# LPC408x_7x register map
File version: 0.7
CPU: CM4 r0p0, little endian, no MPU, no FPU, 3 interrupt priority bits
Registers are 32-bit, read-write, reset 0x0 unless marked. A register's access mark holds for its fields unless they carry their own. Offsets are from the block's base; [hi:lo] are bit positions; {n}, {i} and the like mark numbered series; 'fields as' and 'values as' point back to an identical list.

## UART4
Base 0x400A4000
0x00 RBR ro reset not defined read-modifies — Receiver Buffer Register. Contains the next received character to be read (DLAB =0).
  [7:0] RBR — The UART4 Receiver Buffer Register contains the oldest received byte in the UART4 Rx FIFO.
0x00 THR wo reset not defined (alternate view of RBR) — Transmit Holding Register. The next character to be transmitted is written here (DLAB =0).
  [7:0] THR — Writing to the UART4 Transmit Holding Register causes the data to be stored in the UART4 transmit FIFO. The byte will be sent when it reaches the bottom of the FIFO and the transmitter is available.
0x00 DLL reset 0x1 (alternate view of RBR) — Divisor Latch LSB. Least significant byte of the baud rate divisor value. The full divisor is used to generate a baud rate from the fractional rate divider (DLAB =1).
  [7:0] DLLSB — The UART4 Divisor Latch LSB Register, along with the U4DLM register, determines the baud rate of the UART4.
0x04 DLM reset 0x1 — Divisor Latch MSB. Most significant byte of the baud rate divisor value. The full divisor is used to generate a baud rate from the fractional rate divider (DLAB =1).
  [7:0] DLMSB — The UART4 Divisor Latch MSB Register, along with the U0DLL register, determines the baud rate of the UART4.
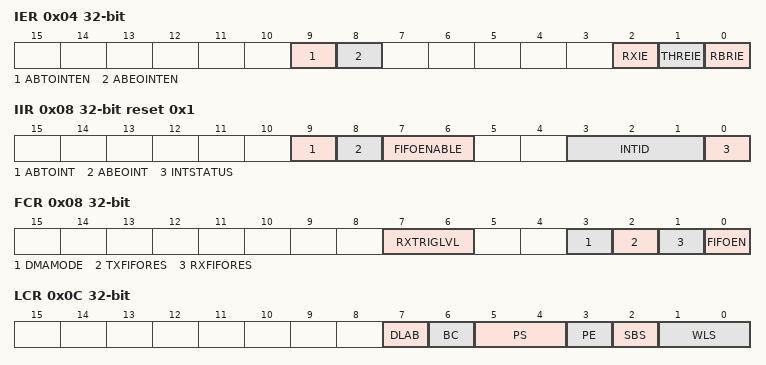
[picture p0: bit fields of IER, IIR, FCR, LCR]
0x04 IER (alternate view of DLM) — Interrupt Enable Register. Contains individual interrupt enable bits for the 7 potential UART interrupts (DLAB =0).
  [9] ABTOINTEN — Enables the auto-baud time-out interrupt.
    0=DISABLE_AUTO_BAUD_TI (Disable auto-baud time-out Interrupt.); 1=ENABLE_AUTO_BAUD_TIM (Enable auto-baud time-out Interrupt.)
  [8] ABEOINTEN — Enables the end of auto-baud interrupt.
    0=DISABLE_END_OF_AUTO_ (Disable end of auto-baud Interrupt.); 1=ENABLE_END_OF_AUTO_B (Enable end of auto-baud Interrupt.)
  [2] RXIE — RX Line Status Interrupt Enable. Enables the UARTn RX line status interrupts. The status of this interrupt can be read from UnLSR[4:1].
    0=DISABLE_THE_RX_LINE_ (Disable the RX line status interrupts.); 1=ENABLE_THE_RX_LINE_S (Enable the RX line status interrupts.)
  [1] THREIE — THRE Interrupt Enable. Enables the THRE interrupt for UARTn. The status of this can be read from UnLSR[5].
    0=DISABLE_THE_THRE_INT (Disable the THRE interrupts.); 1=ENABLE_THE_THRE_INTE (Enable the THRE interrupts.)
  [0] RBRIE — RBR Interrupt Enable. Enables the Receive Data Available interrupt for UARTn. It also controls the Character Receive Time-out interrupt.
    0=DISABLE_THE_RDA_INTE (Disable the RDA interrupts.); 1=ENABLE_THE_RDA_INTER (Enable the RDA interrupts.)
0x08 IIR ro reset 0x1 — Interrupt ID Register. Identifies which interrupt(s) are pending.
  [9] ABTOINT — Auto-baud time-out interrupt. True if auto-baud has timed out and interrupt is enabled.
  [8] ABEOINT — End of auto-baud interrupt. True if auto-baud has finished successfully and interrupt is enabled.
  [7:6] FIFOENABLE — Copies of U4FCR[0].
  [3:1] INTID — Interrupt identification. U4IER[3:1] identifies an interrupt corresponding to the UART4 Rx or TX FIFO. All other combinations of U4IER[3:1] not listed below are reserved (000,100,101,111).
    3=1_RECEIVE_LINE_S (1 - Receive Line Status (RLS).); 2=2A__RECEIVE_DATA_AV (2a - Receive Data Available (RDA).); 6=2B__CHARACTER_TIME_ (2b - Character Time-out Indicator (CTI).); 1=3_THRE_INTERRUPT
  [0] INTSTATUS — Interrupt status. Note that U4IIR[0] is active low. The pending interrupt can be determined by evaluating U4IIR[3:1].
    0=AT_LEAST_ONE_INTERRU (At least one interrupt is pending.); 1=NO_INTERRUPT_IS_PEND (No interrupt is pending.)
0x08 FCR wo (alternate view of IIR) — FIFO Control Register. Controls UART FIFO usage and modes.
  [7:6] RXTRIGLVL — RX Trigger Level. These two bits determine how many receiver UARTn FIFO characters must be written before an interrupt or DMA request is activated.
    0=TRIGGER_LEVEL_0_1_C (Trigger level 0 (1 character or 0x01).); 1=TRIGGER_LEVEL_1_4_C (Trigger level 1 (4 characters or 0x04).); 2=TRIGGER_LEVEL_2_8_C (Trigger level 2 (8 characters or 0x08).); 3=TRIGGER_LEVEL_3_14_ (Trigger level 3 (14 characters or 0x0E).)
  [3] DMAMODE — DMA Mode Select. When the FIFO enable (bit 0 of this register) is set, this bit selects the DMA mode. See Section 20.6.6.1.
  [2] TXFIFORES — TX FIFO Reset.
    0=NO_IMPACT_ON_EITHER_ (No impact on either of UARTn FIFOs.); 1=WRITING_A_LOGIC_1_TO (Writing a logic 1 to UnFCR[2] will clear all bytes in UARTn TX FIFO, reset the pointer logic. This bit is self-clearing.)
  [1] RXFIFORES — RX FIFO Reset.
    0=NO_IMPACT_ON_EITHER_ (No impact on either of UARTn FIFOs.); 1=WRITING_A_LOGIC_1_TO (Writing a logic 1 to UnFCR[1] will clear all bytes in UARTn Rx FIFO, reset the pointer logic. This bit is self-clearing.)
  [0] FIFOEN — FIFO Enable.
    0=UARTN_FIFOS_ARE_DISA (UARTn FIFOs are disabled. Must not be used in the application.); 1=ACTIVE_HIGH_ENABLE_F (Active high enable for both UARTn Rx and TX FIFOs and UnFCR[7:1] access. This bit must be set for proper UART operation. Any transition on this bit will automatically clear the related UART FIFOs.)
0x0C LCR — Line Control Register. Contains controls for frame formatting and break generation.
  [7] DLAB — Divisor Latch Access Bit
    0=DISABLE_ACCESS_TO_DI (Disable access to Divisor Latches.); 1=ENABLE_ACCESS_TO_DIV (Enable access to Divisor Latches.)
  [6] BC — Break Control
    0=DISABLE_BREAK_TRANSM (Disable break transmission.); 1=ENABLE_BREAK_TRANSMI (Enable break transmission. Output pin UARTn TXD is forced to logic 0 when UnLCR[6] is active high.)
  [5:4] PS — Parity Select
    0=ODD_PARITY_NUMBER_O (Odd parity. Number of 1s in the transmitted character and the attached parity bit will be odd.); 1=EVEN_PARITY_NUMBER_ (Even Parity. Number of 1s in the transmitted character and the attached parity bit will be even.); 2=FORCED_1_STICK_PARIT (Forced 1 stick parity.); 3=FORCED_0_STICK_PARIT (Forced 0 stick parity.)
  [3] PE — Parity Enable.
    0=DISABLE_PARITY_GENER (Disable parity generation and checking.); 1=ENABLE_PARITY_GENERA (Enable parity generation and checking.)
  [2] SBS — Stop Bit Select
    0=1_STOP_BIT_; 1=2_STOP_BITS_1_5_IF_ (2 stop bits (1.5 if UnLCR[1:0]=00).)
  [1:0] WLS — Word Length Select.
    {v}={v+5}_BIT_CHARACTER_LENG ({v+5}-bit character length) (v=0..3)
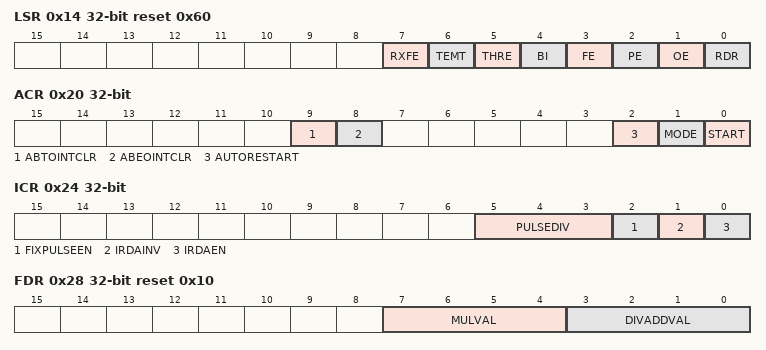
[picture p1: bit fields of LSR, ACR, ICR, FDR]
0x14 LSR ro reset 0x60 read-modifies — Line Status Register. Contains flags for transmit and receive status, including line errors.
  [7] RXFE — Error in RX FIFO . UnLSR[7] is set when a character with a Rx error such as framing error, parity error or break interrupt, is loaded into the UnRBR. This bit is cleared when the UnLSR register is read and there are no subsequent errors in the UARTn FIFO.
    0=UNRBR_CONTAINS_NO_UA (UnRBR contains no UARTn RX errors or UnFCR[0]=0.); 1=UARTN_RBR_CONTAINS_A (UARTn RBR contains at least one UARTn RX error.)
  [6] TEMT — Transmitter Empty. TEMT is set when both UnTHR and UnTSR are empty; TEMT is cleared when either the UnTSR or the UnTHR contain valid data.
    0=VALID_DATA (UnTHR and/or the UnTSR contains valid data.); 1=EMPTY (UnTHR and the UnTSR are empty.)
  [5] THRE — Transmitter Holding Register Empty. THRE is set immediately upon detection of an empty UARTn THR and is cleared on a UnTHR write.
    0=UNTHR_CONTAINS_VALID (UnTHR contains valid data.); 1=UNTHR_IS_EMPTY_
  [4] BI — Break Interrupt. When RXDn is held in the spacing state (all zeroes) for one full character transmission (start, data, parity, stop), a break interrupt occurs. Once the break condition has been detected, the receiver goes idle until RXDn goes to marking state (all ones). An UnLSR read clears this status bit. The time of break detection is dependent on UnFCR[0]. Note: The break interrupt is associated with the character at the top of the UARTn RBR FIFO.
    0=BREAK_INTERRUPT_STAT (Break interrupt status is inactive.); 1=BREAK_INTERRUPT_STAT (Break interrupt status is active.)
  [3] FE — Framing Error. When the stop bit of a received character is a logic 0, a framing error occurs. An UnLSR read clears UnLSR[3]. The time of the framing error detection is dependent on UnFCR[0]. Upon detection of a framing error, the Rx will attempt to resynchronize to the data and assume that the bad stop bit is actually an early start bit. However, it cannot be assumed that the next received byte will be correct even if there is no Framing Error. Note: A framing error is associated with the character at the top of the UARTn RBR FIFO.
    0=FRAMING_ERROR_STATUS (Framing error status is inactive.); 1=FRAMING_ERROR_STATUS (Framing error status is active.)
  [2] PE — Parity Error. When the parity bit of a received character is in the wrong state, a parity error occurs. An UnLSR read clears UnLSR[2]. Time of parity error detection is dependent on UnFCR[0]. Note: A parity error is associated with the character at the top of the UARTn RBR FIFO.
    0=PARITY_ERROR_STATUS_ (Parity error status is inactive.); 1=PARITY_ERROR_STATUS_ (Parity error status is active.)
  [1] OE — Overrun Error. The overrun error condition is set as soon as it occurs. An UnLSR read clears UnLSR[1]. UnLSR[1] is set when UARTn RSR has a new character assembled and the UARTn RBR FIFO is full. In this case, the UARTn RBR FIFO will not be overwritten and the character in the UARTn RSR will be lost.
    0=OVERRUN_ERROR_STATUS (Overrun error status is inactive.); 1=OVERRUN_ERROR_STATUS (Overrun error status is active.)
  [0] RDR — Receiver Data Ready. UnLSR[0] is set when the UnRBR holds an unread character and is cleared when the UARTn RBR FIFO is empty.
    0=THE_UARTN_RECEIVER_F (The UARTn receiver FIFO is empty.); 1=THE_UARTN_RECEIVER_F (The UARTn receiver FIFO is not empty.)
0x1C SCR — Scratch Pad Register. 8-bit temporary storage for software.
  [7:0] Pad — A readable, writable byte.
0x20 ACR — Auto-baud Control Register. Contains controls for the auto-baud feature.
  [9] ABTOINTCLR — Auto-baud time-out interrupt clear bit (write-only accessible). Writing a 1 will clear the corresponding interrupt in the UnIIR. Writing a 0 has no impact.
    0=NO_IMPACT_; 1=CLEAR_THE_CORRESPOND (Clear the corresponding interrupt in the IIR.)
  [8] ABEOINTCLR — End of auto-baud interrupt clear bit (write-only accessible). Writing a 1 will clear the corresponding interrupt in the UnIIR. Writing a 0 has no impact.
    values as ABTOINTCLR
  [2] AUTORESTART — Restart bit.
    0=NO_RESTART_; 1=RESTART_IN_CASE_OF_T (Restart in case of time-out (counter restarts at next UARTn Rx falling edge))
  [1] MODE — Auto-baud mode select bit.
    0=MODE_0_; 1=MODE_1_
  [0] START — Start bit. This bit is automatically cleared after auto-baud completion.
    0=AUTO_BAUD_STOP_AUTO (Auto-baud stop (auto-baud is not running).); 1=AUTO_BAUD_START_AUT (Auto-baud start (auto-baud is running). Auto-baud run bit. This bit is automatically cleared after auto-baud completion.)
0x24 ICR — IrDA Control Register. Enables and configures the IrDA mode.
  [5:3] PULSEDIV — Configures the pulse when FixPulseEn = 1.
    0=2XTPCLK; 1=4XTPCLK; 2=8XTPCLK; 3=16XTPCLK; 4=32XTPCLK; 5=64XTPCLK; 6=128XTPCLK; 7=256XTPCLK
  [2] FIXPULSEEN — IrDA fixed pulse width mode.
    0=DISABLED_; 1=ENABLED_
  [1] IRDAINV — Serial input direction.
    0=NOT_INVERTED_; 1=INVERTED_THIS_HAS_N (Inverted. This has no effect on the serial output.)
  [0] IRDAEN — IrDA mode
    0=DISABLED_IRDA_MODE_ (Disabled. IrDA mode on UART4 is disabled, UART4 acts as a standard UART.); 1=ENABLED_IRDA_MODE_O (Enabled. IrDA mode on UART4 is enabled.)
0x28 FDR reset 0x10 — Fractional Divider Register. Generates a clock input for the baud rate divider.
  [7:4] MULVAL — Baud Rate pre-scaler multiplier value. This field must be greater or equal 1 for UART4 to operate properly, regardless of whether the fractional baud rate generator is used or not.
  [3:0] DIVADDVAL — Baud Rate generation pre-scaler divisor value. If this field is 0, fractional baud rate generator will not impact the UART4 baud rate.
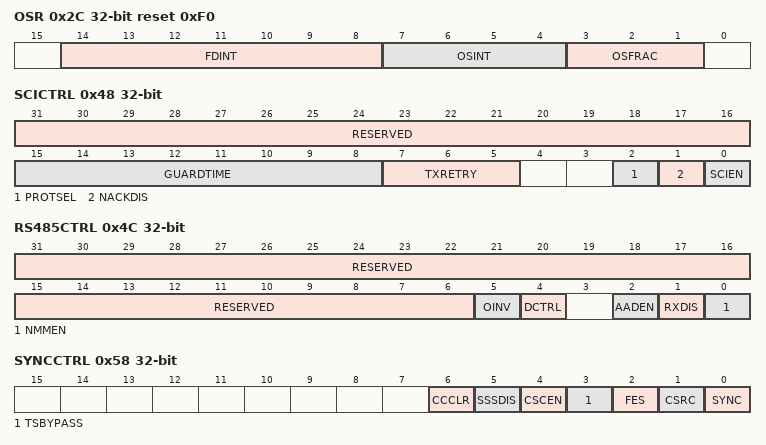
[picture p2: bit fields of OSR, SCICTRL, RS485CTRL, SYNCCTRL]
0x2C OSR reset 0xF0 — Oversampling register. Controls the degree of oversampling during each bit time.
  [14:8] FDINT — In smartcard mode, these bits act as a more-significant extension of the OSint field, allowing an oversampling ratio up to 2048 as required by ISO7816-3. In smartcard mode, bits 14:4 should initially be set to 371, yielding an oversampling ratio of 372.
  [7:4] OSINT — Integer part of the oversampling ratio, minus 1. The reset values equate to the normal operating mode of 16 input clocks per bit time.
  [3:1] OSFRAC — Fractional part of the oversampling ratio, in units of 1/8th of an input clock period. (001 = 0.125, ..., 111 = 0.875)
0x48 SCICTRL — Smart Card Interface control register. Enables and configures the smartcard Interface feature.
  [31:16] RESERVED — Reserved, user software should not write ones to reserved bits. The value read from a reserved bit is not defined.
  [15:8] GUARDTIME — Extra guard time. No extra guard time (0x0) results in a standard guard time as defined in ISO 7816-3, depending on the protocol type. A guard time of 0xFF indicates a minimal guard time as defined for the selected protocol.
  [7:5] TXRETRY — Maximum number of retransmissions in case of a negative acknowledge (protocol T=0). When the retry counter is exceeded, the USART will be locked until the FIFO is cleared. A TX error interrupt is generated when enabled.
  [2] PROTSEL — Protocol selection as defined in the ISO7816-3 standard.
    0=T_EQ_0 (T = 0); 1=T_EQ_1 (T = 1)
  [1] NACKDIS — NACK response disable. Only applicable in T=0.
    0=A_NACK_RESPONSE_IS_E (A NACK response is enabled.); 1=A_NACK_RESPONSE_IS_I (A NACK response is inhibited.)
  [0] SCIEN — Smart Card Interface Enable.
    0=SMART_CARD_INTERFACE (Smart card interface disabled.); 1=ASYNCHRONOUS_HALF_DU (Asynchronous half duplex smart card interface is enabled.)
0x4C RS485CTRL — RS-485/EIA-485 Control. Contains controls to configure various aspects of RS-485/EIA-485 modes.
  [31:6] RESERVED — Reserved, user software should not write ones to reserved bits. The value read from a reserved bit is not defined.
  [5] OINV — Direction control pin polarity. This bit reverses the polarity of the direction control signal on the DIR pin.
    0=LOW_THE_DIRECTION_C (Low. The direction control pin will be driven to logic 0 when the transmitter has data to be sent. It will be driven to logic 1 after the last bit of data has been transmitted.); 1=HIGH_THE_DIRECTION_ (High. The direction control pin will be driven to logic 1 when the transmitter has data to be sent. It will be driven to logic 0 after the last bit of data has been transmitted.)
  [4] DCTRL — Direction control for DIR pin.
    0=DISABLE_AUTO_DIRECTI (Disable Auto Direction Control.); 1=ENABLE_AUTO_DIRECTIO (Enable Auto Direction Control.)
  [2] AADEN — AAD enable
    0=DISABLED_; 1=ENABLED_
  [1] RXDIS — Receiver enable.
    0=ENABLED_; 1=DISABLED_
  [0] NMMEN — NMM enable.
    0=DISABLED (RS-485/EIA-485 Normal Multidrop Mode (NMM) is disabled.); 1=ENABLED (RS-485/EIA-485 Normal Multidrop Mode (NMM) is enabled. In this mode, an address is detected when a received byte causes the USART to set the parity error and generate an interrupt. See Section 20.6.18 RS-485/EIA-485 modes of operation.)
0x50 RS485ADRMATCH — RS-485/EIA-485 address match. Contains the address match value for RS-485/EIA-485 mode.
  [7:0] ADRMATCH — Contains the address match value.
0x54 RS485DLY — RS-485/EIA-485 direction control delay.
  [7:0] DLY — Contains the direction control (U4OE) delay value. This register works in conjunction with an 8-bit counter.
0x58 SYNCCTRL — Synchronous mode control register.
  [6] CCCLR — Continuous clock clear
    0=CSCEN_IS_UNDER_SOFTW (CSCEN is under software control.); 1=HARDWARE_CLEARS_CSCE (Hardware clears CSCEN after each character is received.)
  [5] SSSDIS — Start/stop bits
    0=SEND_START_AND_STOP_ (Send start and stop bits as in other modes.); 1=NOSTARTSTOPBIT (Do not send start/stop bits.)
  [4] CSCEN — Continuous master clock enable (used only when CSRC is 1)
    0=SCLK_CYCLES_ONLY_WHE (SCLK cycles only when characters are being sent on TxD); 1=SCLK_RUNS_CONTINUOUS (SCLK runs continuously (characters can be received on RxD independently from transmission on TxD))
  [3] TSBYPASS — Transmit synchronization bypass in synchronous slave mode.
    0=THE_INPUT_CLOCK_IS_S (The input clock is synchronized prior to being used in clock edge detection logic.); 1=THE_INPUT_CLOCK_IS_N (The input clock is not synchronized prior to being used in clock edge detection logic. This allows for a high er input clock rate at the expense of potential metastability.)
  [2] FES — Falling edge sampling.
    0=RXD_IS_SAMPLED_ON_TH (RxD is sampled on the rising edge of SCLK); 1=RXD_IS_SAMPLED_ON_TH (RxD is sampled on the falling edge of SCLK)
  [1] CSRC — Clock source select.
    0=SYNCHRONOUS_SLAVE_MO (Synchronous slave mode (SCLK in)); 1=SYNCHRONOUS_MASTER_M (Synchronous master mode (SCLK out))
  [0] SYNC — Enables synchronous mode.
    0=DISABLED; 1=ENABLED
